# MSS_TOPRCM register map
Vendor: Texas Instruments
Registers are 32-bit, read-write, no defined reset value unless marked. A register's access mark holds for its fields unless they carry their own. Offsets are as the file gives them; [hi:lo] are bit positions; {n}, {i} and the like mark numbered series; <NAME> marks a mode.

## MSS_TOPRCM (part 2 of 2)
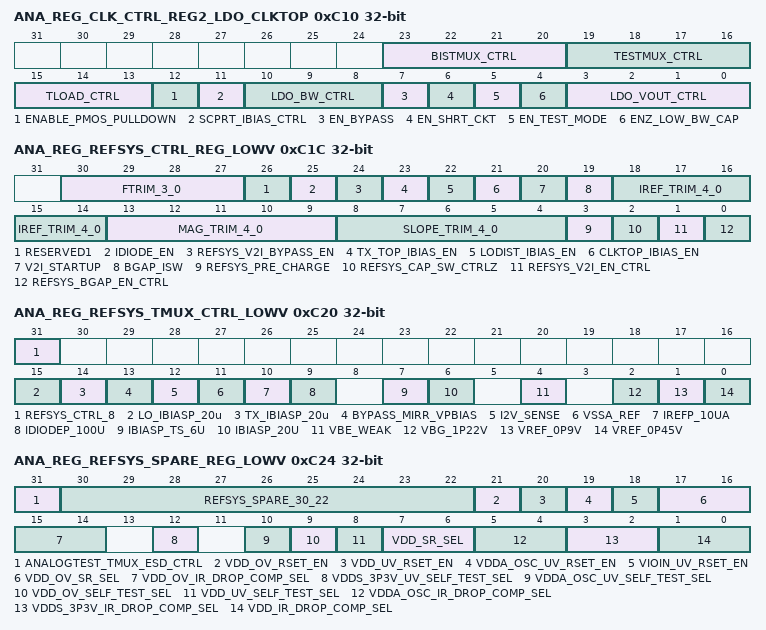
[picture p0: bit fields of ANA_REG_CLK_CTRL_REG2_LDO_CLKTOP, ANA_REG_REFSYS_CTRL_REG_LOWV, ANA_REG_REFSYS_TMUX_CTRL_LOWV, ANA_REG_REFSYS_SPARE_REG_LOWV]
0xC10 ANA_REG_CLK_CTRL_REG2_LDO_CLKTOP
  [23:20] BISTMUX_CTRL — SLICER LDO BIST MUX CONTROL (ONE HOT) Analog MUX enables to BIST output port 0000 = HI-Z Output 0001 = VBG_0P9*10/9 =1.0 V 0010 = VDD18*0.5 = 0.9V 0100 = VLDO Output * 0.6 1000 = Floating WARNING: Enabling more than one bit may damage the device 0x4 = Functional Reset
  [19:16] TESTMUX_CTRL — SLICER LDO TEST MUX CONTROL (ONE HOT) Analog MUX enables to test output port 0000 = HI-Z Output 0001 = 0.6 * VLDO_OUT 0010 = VDD18*0.5 = 0.9V 0100 = VSSA 1000 = LDO Test Current (12.5uA) WARNING: Enabling more than one bit may damage the device 0x0 = Functional Reset
  [15:13] TLOAD_CTRL — SLICER LDO TLOAD CONTROL updated description needed 0x0 = Functional Reset
  [12] ENABLE_PMOS_PULLDOWN — SLICER LDO PMOS PULL DOWN ENABLE 0 = Slicer LDO PMOS Pull Down disabled 1 = Slicer LDO PMOS Pull Down enabled 0x0 = Functional Reset
  [11] SCPRT_IBIAS_CTRL — SLICER LDO SHORT CKT PROTECTION IBIAS CONTROL 0 = Nominal short circuit bias with nominal short circuit current limit 1 = 2X Nominal short circuit bias with higher short circuit current limit 0x0 = Functional Reset
  [10:8] LDO_BW_CTRL — SLICER LDO BANDWIDTH CONTROL need updated description 0x7 = Functional Reset
  [7] EN_BYPASS — SLICER LDO BYPASS ENABLE 0 = Slicer LDO in normal mode 1 = Slicer LDO Bypassed with external voltage 0x0 = Functional Reset
  [6] EN_SHRT_CKT — SLICER LDO SHORT CKT PROTECTION ENABLE 0 = Slicer LDO Short Ckt Protection Disabled 1 = Slicer LDO Short Ckt Protection Enabled 0x0= Functional Reset
  [5] EN_TEST_MODE — SLICER LDO TEST MODE ENABLE 0 = Slicer LDO TEST MODE Disabled 1 = Slicer LDO TEST MODE Enabled 0x0 = Functional Reset
  [4] ENZ_LOW_BW_CAP — SLICER LDO LOW BW MODE DISABLE 1 = Slicer LDO Low BW mode Enabled 0 = Slicer LDO Low BW mode Disabled 0x1 = Functional Reset
  [3:0] LDO_VOUT_CTRL — SLICER LDO VOUT TRIM NEEDS updated description 0x0 = Functional Reset
0xC18 ANA_REG_CLK_STATUS_REG ro
  [0] SLICER_LDO_SC_OUT — SLICER LDO SHORT CIRCUIT INDICATOR 0 = Normal operation 1 = LDO Output Short Circuit Detected
0xC1C ANA_REG_REFSYS_CTRL_REG_LOWV
  [30:27] FTRIM_3_0 — Filter TRIM Control 0x0 = Functional Reset
  [26] RESERVED1 — <7> Unused 0x0 = Functional Reset
  [25] IDIODE_EN — <6> Idiode Active Low Control --> Unused in TPR, Reserved for AWR <0> - Enable <1> - Disable 0x0= Functional Reset
  [24] REFSYS_V2I_BYPASS_EN — <5> REFSYS V2I By-Pass Enable 0x0 = Functional Reset
  [23] TX_TOP_IBIAS_EN — <4> TX TOP IBIAS EN--> Unused in TPR, Reserved for AWR 0x1 = Functional Reset
  [22] LODIST_IBIAS_EN — <3> LO DIST BIAS EN --> Unused in TPR, Reserved for AWR 0x1 = Functional Reset
  [21] CLKTOP_IBIAS_EN — <2> CLK TOP IBIAS EN 0x1 = Functional Reset
  [20] V2I_STARTUP — <1> V2I Startup 0x0 = Functional Reset
  [19] BGAP_ISW — <0> BGAP ISW STARTUP 0x0 = Functional Reset
  [18:14] IREF_TRIM_4_0 — Default Resistor Trim for NOM LOT 0x02 = Functional Reset
  [13:9] MAG_TRIM_4_0 — Default Magnitude Trim for NOM LOT 0x00 = Functional Reset
  [8:4] SLOPE_TRIM_4_0 — Default Slope Trim for NOM LOT 0x0D = Functional Reset
  [3] REFSYS_PRE_CHARGE — REFSYS Pre Charge Control 0 = Disable Pre Charge Block 1 = Enable Pre Charge Block 0x0 = Functional Reset
  [2] REFSYS_CAP_SW_CTRLZ — REFSYS Cap Switch Control 0 = Switch External Cap to reference output 1 = Disconnect External Cap to Reference output 0x0 = Functional Reset
  [1] REFSYS_V2I_EN_CTRL — REFSYS Enable Control 0 = Disable V2I REFSYS 1 = Enable V2I REFSYS 0x1 = Functional Reset
  [0] REFSYS_BGAP_EN_CTRL — REFSYS Enable Control 0 = Disable REFSYS 1 = Enable REFSYS 0x1 = Functional Reset
0xC20 ANA_REG_REFSYS_TMUX_CTRL_LOWV
  [31] REFSYS_CTRL_8 — REFSYS Test Mux Enable. Other bits in Bus are One-hot. This control enabled in sync with other one hot control bits in Reg 0 = TMUX Disabled 1 = TMUX Enabled 0x0 = Functional Reset
  [15] LO_IBIASP_20u — <15> LO IBG BIASP 20uA (TMUX One-Hot) 0x0 = Functional Reset
  [14] TX_IBIASP_20u — <14> TX IBG BIASP 20uA (TMUX One-Hot) 0x0 = Functional Reset
  [13] BYPASS_MIRR_VPBIAS — VPBIAS Control for IREF Gen Test Mode V2I By-Pass Feature 0x0 = Functional Reset
  [12] I2V_SENSE — Sense Voltage from the BIST I2V cinversion of 20u and 6u bias current paths Sense voltage of 1V for BIST select<6> Sense voltage of 0.3V for BIST select<7> 0x0 = Functional Reset
  [11] VSSA_REF — <11> VSSA REF (TMUX One-Hot) 0x0 = Functional Reset
  [10] IREFP_10UA — <10> IREFP 10uA (TMUX One-Hot) 0x0 = Functional Reset
  [9] IDIODEP_100U — <9> Idiode BIASP 100uA (TMUX One-Hot) 0x0 = Functional Reset
  [7] IBIASP_TS_6U — <7> IBG BIASP TS 6uA (TMUX One-Hot) 0x0 = Functional Reset
  [6] IBIASP_20U — <6> CLK IBG BIASP 20uA (TMUX One-Hot) 0x0 = Functional Reset
  [4] VBE_WEAK — <4> - VBE Weak (TMUX One-Hot) 0x0 = Functional Reset
  [2] VBG_1P22V — <2> - VBG 1.22V (TMUX One-Hot) 0x0 = Functional Reset
  [1] VREF_0P9V — <1> - VREF 0P9V (Cap Node) (TMUX One-Hot) 0x0 = Functional Reset
  [0] VREF_0P45V — <0> - VREF 0P45 (TMUX One-Hot) 0x0 = Functional Reset
0xC24 ANA_REG_REFSYS_SPARE_REG_LOWV
  [31] ANALOGTEST_TMUX_ESD_CTRL — ANALOGTEST TMUX ESD CTRL in Pad-Frame (formerly RX_REFSYS_TMUX_SPARE_CTRL_LOWV<31> in AWR/IWR devices, but RX does not exist in TPR) 0x0 = Functional Reset
  [30:22] REFSYS_SPARE_30_22 — Reserved Reads return 0x0 and writes have no effect. 0x000 = Functional Reset
  [21] VDD_OV_RSET_EN — If asserted, VDD_OV will automatically reset the device through hardware control. Otherwise, UV flag will propagate to the digital where the CPU will need to take action. 0x0 = Functional Reset
  [20] VDD_UV_RSET_EN — If asserted, VDD_UV will automatically reset the device through hardware control. Otherwise, UV flag will propagate to the digital where the CPU will need to take action. 0x0 = Functional Reset
  [19] VDDA_OSC_UV_RSET_EN — If asserted, VDDA_OSC_UV will automatically reset the device through hardware control. Otherwise, UV flag will propagate to the digital where the CPU will need to take action. 0x0 = Functional Reset
  [18] VIOIN_UV_RSET_EN — If asserted, VIOIN_UV will automatically reset the device through hardware control. Otherwise, UV flag will propagate to the digital where the CPU will need to take action. 0x0 = Functional Reset
  [17:16] VDD_OV_SR_SEL — Final level of VDD 1.2V VMON OV Reference Selection See definition in REFSYS_SPARE_REG<15:14> 0x0 = Functional Reset
  [15:14] VDD_OV_IR_DROP_COMP_SEL — VDD 1.2V VMON OV Reference Selection Reference selection is dependent on REFSYS_SPARE_REG<17:16> programming If REFSYS_SPARE_REG<17:16> = 0x0 0x0 = 0.68V 0x1 = 0.67V 0x2 = 0.66V 0x3 = 0.65V If REFSYS_SPARE_REG<17:16> = 0x1 0x0 = 0.65V 0x1 = 0.64V 0x2 = 0.63V 0x3 = 0.62V If REFSYS_SPARE_REG<17:16> = 0x2 0x0 = 0.62V 0x1 = 0.61V 0x2 = 0.6V 0x3 = 0.59V If REFSYS_SPARE_REG<17:16> = 0x3 0x0 = 0.59V 0x1 = 0.58V 0x2 = 0.57V 0x3 = 0.56V 0x0 = Functional Reset
  [12] VDDS_3P3V_UV_SELF_TEST_SEL — Enable VIOIN Strict UV VMON Self Test If Self-test mode is enabled, VIOIN UV VMON reference is programmed as follows for REFSYS_SPARE_REG<3:2>: 0x0 = 0.66V 0x1 = 0.64V 0x2 = 0.62V 0x3 = 0.6V 0x0 = Functional Reset
  [10] VDDA_OSC_UV_SELF_TEST_SEL — Enable VDDA_OSC Strict UV VMON Self Test If Self-test mode is enabled, VDDA_OSC UV VMON reference is programmed as follows for REFSYS_SPARE_REG<5:4>: 0x0 = 0.66V 0x1 = 0.64V 0x2 = 0.62V 0x3 = 0.6V 0x0 = Functional Reset
  [9] VDD_OV_SELF_TEST_SEL — Enable 1.2V VDD Strict OV VMON Self Test If Self-test mode is enabled, VDD 1.2V VMON OV reference is programmed based on REFSYS_SPARE_REG<1:0> as follows: If REFSYS_SPARE_REG<7:6> = 0x0, REFSYS_SPARE_REG<1:0>: 0x0 = 0.58V 0x1 = 0.57V 0x2 = 0.56V 0x3 = 0.55V If REFSYS_SPARE_REG<7:6> = 0x1, REFSYS_SPARE_REG<1:0>: 0x0 = 0.55V 0x1 = 0.54V 0x2 = 0.53V 0x3 = 0.52V If REFSYS_SPARE_REG<7:6> = 0x2, REFSYS_SPARE_REG<1:0>: 0x0 = 0.53V 0x1 = 0.52V 0x2 = 0.51V 0x3 = 0.5V If REFSYS_SPARE_REG<7:6> = 0x3, REFSYS_SPARE_REG<1:0>: 0x0 = 0.51V 0x1 = 0.5V 0x2 = 0.49V 0x3 = 0.48V 0x0 = Functional Reset
  [8] VDD_UV_SELF_TEST_SEL — Enable 1.2V VDD Strict UV VMON Self Test If Self-test mode is enabled, VDD 1.2V VMON UV reference is programmed based on REFSYS_SPARE_REG<15:14> as follows: If REFSYS_SPARE_REG<17:16> = 0x0, REFSYS_SPARE_REG<15:14>: 0x0 = 0.68V 0x1 = 0.67V 0x2 = 0.66V 0x3 = 0.65V If REFSYS_SPARE_REG<17:16> = 0x1, REFSYS_SPARE_REG<15:14>: 0x0 = 0.65V 0x1 = 0.64V 0x2 = 0.63V 0x3 = 0.62V If REFSYS_SPARE_REG<17:16> = 0x2, REFSYS_SPARE_REG<15:14>: 0x0 = 0.62V 0x1 = 0.61V 0x2 = 0.6V 0x3 = 0.59V If REFSYS_SPARE_REG<17:16> = 0x3, REFSYS_SPARE_REG<15:14>: 0x0 = 0.59V 0x1 = 0.58V 0x2 = 0.57V 0x3 = 0.56V 0x0 = Functional Reset
  [7:6] VDD_SR_SEL — Final level of VDD 1.2V VMON UV Reference Selection See definition in REFSYS_SPARE_REG<1:0> 0x0 = Functional Reset
  [5:4] VDDA_OSC_IR_DROP_COMP_SEL — VDDA_OSC UV VMON Reference Selection 0x0 = 0.56V 0x1 = 0.54V 0x2 = 0.52V 0x3 = 0.5V 0x0 = Functional Reset
  [3:2] VDDS_3P3V_IR_DROP_COMP_SEL — VIOIN VMON UV Reference Selection 0x0 = 0.56V 0x1 = 0.54V 0x2 = 0.52V 0x3 = 0.5V 0x0 = Functional Reset
  [1:0] VDD_IR_DROP_COMP_SEL — VDD 1.2V VMON UV Reference Selection Reference selection is dependent on REFSYS_SPARE_REG<7:6> programming If REFSYS_SPARE_REG<7:6> = 0x0 0x0 = 0.58V 0x1 = 0.57V 0x2 = 0.56V 0x3 = 0.55V If REFSYS_SPARE_REG<7:6> = 0x1 0x0 = 0.55V 0x1 = 0.54V 0x2 = 0.53V 0x3 = 0.52V If REFSYS_SPARE_REG<7:6> = 0x2 0x0 = 0.53V 0x1 = 0.52V 0x2 = 0.51V 0x3 = 0.5V If REFSYS_SPARE_REG<7:6> = 0x3 0x0 = 0.51V 0x1 = 0.5V 0x2 = 0.49V 0x3 = 0.48V 0x0 = Functional Reset
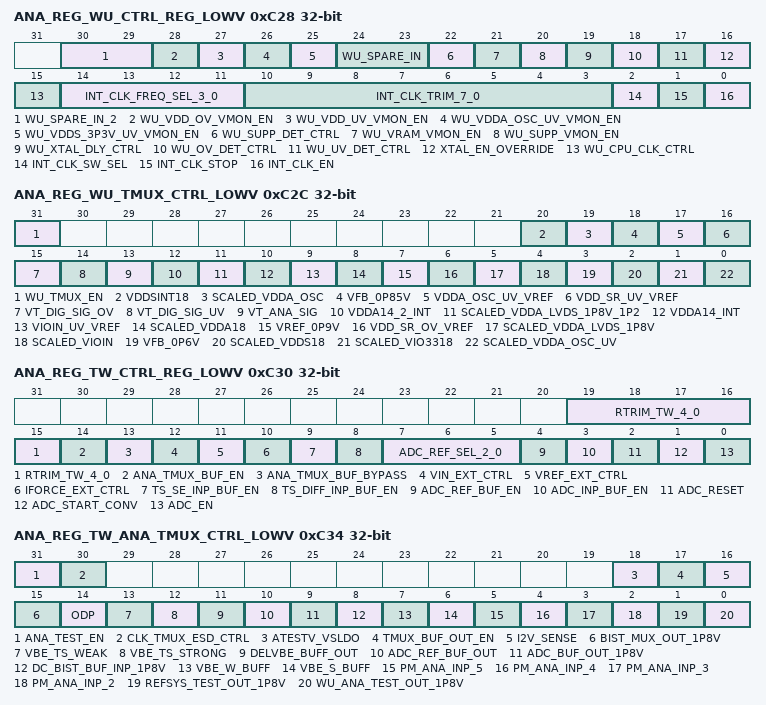
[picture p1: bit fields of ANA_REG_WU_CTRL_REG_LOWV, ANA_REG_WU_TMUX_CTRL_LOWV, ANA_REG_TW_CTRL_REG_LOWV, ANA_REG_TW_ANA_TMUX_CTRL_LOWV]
0xC28 ANA_REG_WU_CTRL_REG_LOWV
  [30:29] WU_SPARE_IN_2 — WU Spare Control 0x3 = Functional Reset
  [28] WU_VDD_OV_VMON_EN — WU VDD OV VMON Enable Control 0 = VDD OV Detect Disabled 1 = VDD OV Detect Enabled 0x0 = Functional Reset
  [27] WU_VDD_UV_VMON_EN — WU VDD UV VMON Enable Control 0 = VDD UV Detect Disabled 1 = VDD UV Detect Enabled 0x0 = Functional Reset
  [26] WU_VDDA_OSC_UV_VMON_EN — WU VDDA OSC UV VMON Enable Control 0 = VDDA OSC UV Detect Disabled 1 = VDDA OSC UV Detect Enabled 0x0 = Functional Reset
  [25] WU_VDDS_3P3V_UV_VMON_EN — WU VDDS 3.3V UV VMON Enable Control 0 = VDDS 3.3V UV Detect Disabled 1 = VDDS 3.3V UV Detect Enabled 0x0 = Functional Reset
  [24:23] WU_SPARE_IN — WU Spare Control Change for 1642 ES2P0 Change Name : Newly added OR gates to provide options to bypass crude VDD DET (also refer to <11>) Bit <0> of this field when HIGH over rides the crude VDD_DET, this control is using firmware Bit<0> of this field is WU_CTRL_REG<23> Change for 2243 ES1P0 Using Bit<1>, is WU_CTRL_REG<24> This bit is used to make the reset fix SW controllable. Manshul's email notes-- Since the default value of WU_SPARE_IN<1> is ‘0’, we will have the fix active by default. To disable it, firmware can write this bit to ‘1’ before enabling VMON. 0x0 = Functional Reset
  [22] WU_SUPP_DET_CTRL — WU VMON Detect Status Override Disable in Functional Test SOP 0 = VMON Det Status Override Disabled 1 = VMON Det Status Override Enabled 0x1 = Functional Reset
  [21] WU_VRAM_VMON_EN — WU VRAM VMON Enable Control 0 = SRAM UV Detect Disabled 1 = SRAM UV Detect Enabled 0x1 = Functional Reset
  [20] WU_SUPP_VMON_EN — WU VMON Enable Control 0 = VMON Control Disabled 1 = VMON Control Enabled 0x1 = Functional Reset
  [19] WU_XTAL_DLY_CTRL — Introduce additional delay for XTAL settling 0 = Default delay as per WU-SEQ 1 = Introduce additional delay as per WU-SEQ 0x0 = Functional Reset
  [18] WU_OV_DET_CTRL — WU Over Voltage Detect Control Changed for 1243 ES3P0 (Metal only change from 1642 ES2P0) Change Name : FW control of VDD OV DET EN 1 = OV Detect is disabled 0 = OV Detect is Enabled 0x1 = Functional Reset
  [17] WU_UV_DET_CTRL — WU Under Voltage Detect Control 0 = UV Detect is disabled 1 = UV Detect is Enabled 0x1 = Functional Reset
  [16] XTAL_EN_OVERRIDE — XTAL EN Override (WU-SEQ) Control 0 = XTAL Enable is driven by WU-SEQ detection 1 = Override XTAL Enable if disabled by default 0x0 = Functional Reset
  [15] WU_CPU_CLK_CTRL — WU CLK Control 0 = CLK Monitor Function in Dig Sequencer is disabled 1 = REF CLK Monitor Function is Enabled 0x1 = Functional Reset
  [14:11] INT_CLK_FREQ_SEL_3_0 — WU Internal Clock (RCOSC) Frequency Select Bit<3> is used as override for VMON on Untrimmed devices. Bit <3> is '1' if device REFSYS_TOP is trimmed. Changed on 1642 ES2P0 Change Name : Newly added mux for CLK MON EN options When Bit<2> = 0, MASK_CPU_CLK_OUT_CTRL_LOWV == WU_CTRL_REG<12>, essentially Bit<1> of this field When Bit<2> = 1, MASK_CPU_CLK_OUT_CTRL_LOWV == (original function) INTER_MASK_CPU_CLK_OUT_CTRL_LOWV Change Name : Newly added OR gates to provide options to bypass crude VDD DET (also refer to <23>) Bit <0> of this field when HIGH over rides the crude VDD_DET 0x0 = Functional Reset
  [10:3] INT_CLK_TRIM_7_0 — WU lnternal Clock (RCOSC) Trim 0x4B = Functional Reset (If not trimmed)
  [2] INT_CLK_SW_SEL — WU Internal Clock (RCOSC) SW_SEL 0 = TBD 1 = TBD 0x1 = Functional Reset
  [1] INT_CLK_STOP — WU Internal Clock (RCOSC) STOP 0 = Internal CLK can be enabled 1 = Internal CLK is OFF 0x0 = Functional Reset
  [0] INT_CLK_EN — WU Internal Clock (RCOSC) ENABLE 0 = Internal CLK Disabled 1 = Internal CLK Enabled 0x1 = Functional Reset
0xC2C ANA_REG_WU_TMUX_CTRL_LOWV
  [31] WU_TMUX_EN — WU TMUX Enable 0 = TMUX Disabled 1 = TMUX Enabled 0x0 = Functional Reset
  [20] VDDSINT18 — VIOIN scaled supply for VIOIN Detect Scaling Factor: VIOIN*(52/90) 0x0 = Functional Reset
  [19] SCALED_VDDA_OSC — Scaled VDDA_OSC supply for crude supply detect Scaling Factor: VDDA_OSC*(22/39) 0x0 = Functional Reset
  [18] VFB_0P85V — Scaled VDD 1.2V used as reference for VDDA_OSC crude supply detect 0x0 = Functional Reset
  [17] VDDA_OSC_UV_VREF — Test Mux Control. One Hot Control VDDA_OSC UV VMON reference 0x0 = Functional Reset
  [16] VDD_SR_UV_VREF — Test Mux Control. One Hot Control VDD UV VMON reference 0x0 = Functional Reset
  [15] VT_DIG_SIG_OV — Test Mux Control. One Hot Control Connected to Crude Vt-based VDD OV VMON reference 0x0 = Functional Reset
  [14] VT_DIG_SIG_UV — Test Mux Control. One Hot Control Connected to Crude Vt-based VDD UV VMON reference 0x0 = Functional Reset
  [13] VT_ANA_SIG — Test Mux Control. One Hot Control VT Detect Signal Level on VDDA18_PM in TPR VT Detect Signal Level on VDDA_LVDS_1P8V 0x0 = Functional Reset
  [12] VDDA14_2_INT — Test Mux Control. One Hot Control Tied LO in TPR VIN_13RF2 0x0 = Functional Reset
  [11] SCALED_VDDA_LVDS_1P8V_1P2 — Test Mux Control. One Hot Control Change in TPR VDDS_3P3V IO DET reference (1.8V mode) Scaling Factor: 0.67 * VDDA_LVDS_1P8V 0x0 = Functional Reset
  [10] VDDA14_INT — Test Mux Control. One Hot Control Tied LO in TPR VIN_13RF1 0x0 = Functional Reset
  [9] VIOIN_UV_VREF — Test Mux Control. One Hot Control Reference voltage for VIOIN_UV VMON 0x0 = Functional Reset
  [8] SCALED_VDDA18 — Test Mux Control. One Hot Control Tied LO in TPR Scaling Factor: 0.55 * VIN_18BB 0x0 = Functional Reset
  [7] VREF_0P9V — Test Mux Control. One Hot Control VREF_0P9V 0x0 = Functional Reset
  [6] VDD_SR_OV_VREF — Test Mux Control. One Hot Control VDD OV VMON reference 0x0 = Functional Reset
  [5] SCALED_VDDA_LVDS_1P8V — Test Mux Control. One Hot Control Change in TPR VDDS_3P3V IO DET reference (3.3V mode) Scaling Factor: 0.4 * VDDA_LVDS_1P8V 0x0 = Functional Reset
  [4] SCALED_VIOIN — Test Mux Control. One Hot Control Change for 1642 ES2P0 Change Name : VIOIN & VIN_SRAM connection to GPADC Scaling Factor: 0.289 * VIOIN 0x0 = Functional Reset
  [3] VFB_0P6V — Test Mux Control. One Hot Control Scaling Factor: 0.5 * VDD 0x0 = Functional Reset
  [2] SCALED_VDDS18 — Test Mux Control. One Hot Control Tied LO in TPR Scaling Factor: 0.55 * VDDS18 0x0 = Functional Reset
  [1] SCALED_VIO3318 — Test Mux Control. One Hot Control Scaling Factor: VIOIN/5.5 (3.3V mode), VIOIN/3 (1.8V mode) 0x0 = Functional Reset
  [0] SCALED_VDDA_OSC_UV — Test Mux Control. One Hot Control Scaling Factor: VDDA_OSC/3 0x0 = Functional Reset
0xC30 ANA_REG_TW_CTRL_REG_LOWV
  [19:15] RTRIM_TW_4_0 — RTRIM value to TW routed to BIST MUX IN REFSYS for I2V 0x02 = Functional Reset
  [14] ANA_TMUX_BUF_EN — TW ANA TMUX Buffer Enabled 0 = ANA TMUX Buffer Disabled 1 = ANA TMUX Buffer Enabled 0x0 = Functional Reset
  [13] ANA_TMUX_BUF_BYPASS — TW ANA TMUX Buffer Bypass 0 = ANA TMUX Buffer By-pass Disabled 1 = ANA TMUX Buffer By-pass Enabled 0x0 = Functional Reset
  [12] VIN_EXT_CTRL — TW VIN Control from External Source 0 = External VIN Control Disabled 1 = External VIN Control Enabled 0x0 = Functional Reset
  [11] VREF_EXT_CTRL — TW VREF Control from External SOurce 0 = External VREF Control Disabled 1 = External VREF Control Enabled 0x0 = Functional Reset
  [10] IFORCE_EXT_CTRL — TW Iforce Control from External Source 0 = IFORCE Control Disabled 1 = IFORCE Control Enabled 0x0 = Functional Reset
  [9] TS_SE_INP_BUF_EN — TW ADC TS SE Inp Buffer Enable 0 = Input Buffer disabled 1 = Input Buffer Enabled 0x0 = Functional Reset
  [8] TS_DIFF_INP_BUF_EN — TW ADC TS DIFF Inp Buffer Enable 0 = Input Buffer disabled 1 = Input Buffer Enabled 0x1 = Functional Reset
  [7:5] ADC_REF_SEL_2_0 — TW ADC Reference Select 0b001 = Reference from Top Refsys 0b010 = Reference from RX Refsys 0b100 = Reference from External Test Pin (CZ/ Trim) 0x001 = Functional Reset
  [4] ADC_REF_BUF_EN — TW ADC Reference Buffer Enable 0 = Input Buffer disabled 1 = Input Buffer Enabled (Default) 0x1 = Functional Reset
  [3] ADC_INP_BUF_EN — TW ADC Input Buffer Enable 0 = Input Buffer disabled 1 = Input Buffer Enabled (Default) 0x1 = Functional Reset
  [2] ADC_RESET — TW ADC Reset (Active High) 0 = ADC Out of Reset 1 = ADC In Reset 0x1 = Functional Reset
  [1] ADC_START_CONV — TW ADC Start Conversion 0x0 = Functional Reset
  [0] ADC_EN — TW ADC Control 0 = ADC Disable 1 = ADC Enable 0x0 = Functional Reset
0xC34 ANA_REG_TW_ANA_TMUX_CTRL_LOWV
  [31] ANA_TEST_EN — TW ANA Test MUX Enabled 0 = ANA TMUX Control Disabled 1 = ANA TMUX Control Enabled 0x0 = Functional Reset
  [30] CLK_TMUX_ESD_CTRL — CLK TMUX ESD CTRL in Pad-Frame 0x0 = Functional Reset
  [18] ATESTV_VSLDO — Enable Output of ATESTV of VSLDO 0x0 = Functional Reset
  [17] TMUX_BUF_OUT_EN — Enable Output of TMUX buffer 0x0 = Functional Reset
  [16] I2V_SENSE — I2V Sense Voltage of External IREF Forced. IREF is forced thru' ANAMUX Pin and enabling TW_CTRL_REG<10> 0x0 = Functional Reset
  [15] BIST_MUX_OUT_1P8V — BIST Mux output pre ADC input Buffer 0x0 = Functional Reset
  [14] ODP — Ibias current from Top Refsys for measurement on Test Pin 0x0 = Functional Reset
  [13] VBE_TS_WEAK — Single PNP Sense voltage for TSENSE selected 0x0 = Functional Reset
  [12] VBE_TS_STRONG — Multi PNP Sense voltage for TSENSE selected 0x0 = Functional Reset
  [11] DELVBE_BUFF_OUT — Difference TSENSE signal delVbe scaled and buffered for chosen TSENSE element 0x0 = Functional Reset
  [10] ADC_REF_BUF_OUT — ADC reference buffer out to Test Pin 0x0 = Functional Reset
  [9] ADC_BUF_OUT_1P8V — Buffered output of ADC inputs to GPADC 0x0 = Functional Reset
  [8] DC_BIST_BUF_INP_1P8V — DC BIST Buffered output of RX, TX, CLK, LO (shorted on to this net). DC BIST one hot control and DC BIST control has to be used to bring relevant signal here 0x0 = Functional Reset
  [7] VBE_W_BUFF — Buffered value of Weak PNP 0x0 = Functional Reset
  [6] VBE_S_BUFF — Buffered value of Strong PNP 0x0 = Functional Reset
  [5] PM_ANA_INP_5 — CLK ANA Test Pin Mapped 0x0 = Functional Reset
  [4] PM_ANA_INP_4 — RX ANA Test Mux Control 0x0 = Functional Reset
  [3] PM_ANA_INP_3 — LODIST ANA Test Mux Control 0x0 = Functional Reset
  [2] PM_ANA_INP_2 — TX PM ANA Test Mux Control 0x0 = Functional Reset
  [1] REFSYS_TEST_OUT_1P8V — Mux Output of Refsys Test Mux. Refsys Test Mux has to be enabled and controlled to bring the internal signal of Refsys Analog - PMTOP 0x0 = Functional Reset
  [0] WU_ANA_TEST_OUT_1P8V — Mux Output of WU Test Mux. WU Test Mux has to be enabled and controlled to bring the internal signal of WU Analog 0x0 = Functional Reset
0xC38 ANA_REG_TW_SPARE_LOWV
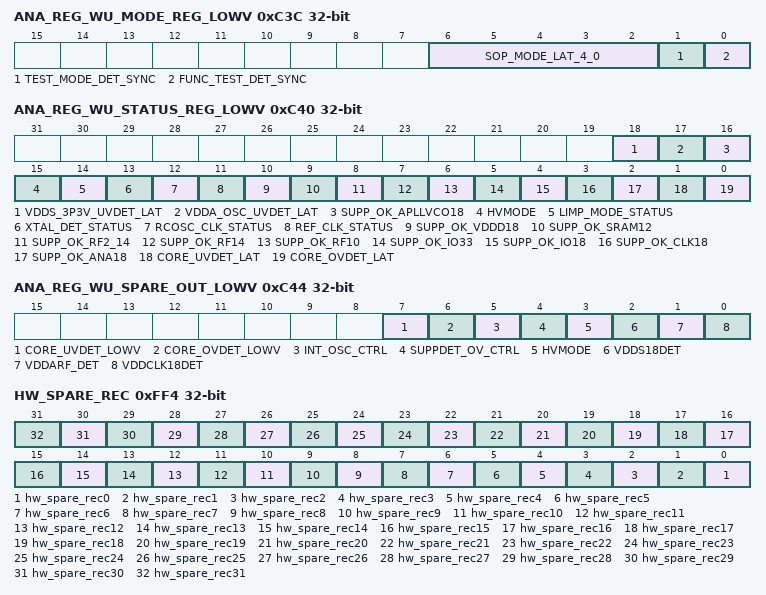
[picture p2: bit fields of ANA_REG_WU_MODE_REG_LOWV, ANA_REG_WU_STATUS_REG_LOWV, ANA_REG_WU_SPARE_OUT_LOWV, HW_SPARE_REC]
0xC3C ANA_REG_WU_MODE_REG_LOWV ro
  [6:2] SOP_MODE_LAT_4_0 — SOP Mode Latched Output
  [1] TEST_MODE_DET_SYNC — Latched Output of Test Mode Detect SOP
  [0] FUNC_TEST_DET_SYNC — Latched Output of Functional Test Mode SOP
0xC40 ANA_REG_WU_STATUS_REG_LOWV ro
  [18] VDDS_3P3V_UVDET_LAT — New in TPR: Latched Value of 3.3V IO UV Detect 0 = UV Detect Not Triggered 1 = UV Detect has Triggered
  [17] VDDA_OSC_UVDET_LAT — Latched value of UV detect of LOMULT 1.8V supply (AWR devices) For TPR, Latched Value of UV Detect of VDDA_OSC 0 = UV Detect Not Triggered 1 = UV Detect has Triggered
  [16] SUPP_OK_APLLVCO18 — Supp Detect output of APLL VCO 1.8V 0 = Supply Not detected 1 = Supply Detected Tied LO in TPR (Unused VMON)
  [15] HVMODE — HVMODE Status from VMON 1 = 3.3V VIO 0 = 1.8V VIO
  [14] LIMP_MODE_STATUS — Ref CLK status at Wake-up 0 = REF CLK is present 1 = REF CLK is absent and CPU CLK Switched to RCOSC
  [13] XTAL_DET_STATUS — XTAL Detect status at Wake-up 0 = XTAL absent 1 = XTAL Present
  [12] RCOSC_CLK_STATUS — RCOSC status at Wake-up 0 = RCOSC CLK absent 1 = RCOSC CLK Present
  [11] REF_CLK_STATUS — Ref CLK status at Wake-up 0 = REF CLK absent 1 = REF CLK Present
  [10] SUPP_OK_VDDD18 — Supp Detect output of LVDS 1.8V 0 = Supply Not detected 1 = Supply Detected Tied LO in TPR (Unused VMON)
  [9] SUPP_OK_SRAM12 — UV Detect Status of SRAM 0 = UV Not Detected 1 = UV Detected Tied LO in TPR (Unused VMON)
  [8] SUPP_OK_RF2_14 — Supp Detect output of RF2 1.4V Pin 0 = Supply Not detected 1 = Supply Detected Tied LO in TPR (Unused VMON)
  [7] SUPP_OK_RF14 — Updated for 1642 ES2P0 Change name : Mux for VIN_13 OK in LDO bypass mode This output bit is always tied low Tied LO in TPR and AWR/IWR devices
  [6] SUPP_OK_RF10 — Updated for 1642 ES2P0 Change name : Mux for VIN_13 OK in LDO bypass mode When RF_LDO_BYPASS_EN = 1, this bit will be high when the supply is > 0.75 When RF_LDO_BYPASS_EN = 0, this bit will be high when the supply is > 1.05 Tied LO in TPR (Unused VMON)
  [5] SUPP_OK_IO33 — Supp Detect output of IO 3.3V 0 = Supply Not detected 1 = Supply Detected
  [4] SUPP_OK_IO18 — Supp Detect output of IO 1.8V 0 = Supply Not detected 1 = Supply Detected
  [3] SUPP_OK_CLK18 — Supp Detect output of CLK 1.8V 0 = Supply Not detected 1 = Supply Detected For TPR, Crude detection of VDDA_OSC
  [2] SUPP_OK_ANA18 — Supp Detect output of Ana 1.8V Tied LO in TPR (unused VMON) 0 = Supply Not detected 1 = Supply Detected
  [1] CORE_UVDET_LAT — Latched Value of UV Detect 0 = UV Detect Not Triggered 1 = UV Detect has Triggered
  [0] CORE_OVDET_LAT — Latched Value of OV Detect 0 = OV Detect Not Triggered 1 = OV Detect has Triggered
0xC44 ANA_REG_WU_SPARE_OUT_LOWV ro
  [7] CORE_UVDET_LOWV — UV Detect of Core Supply-Unlatched
  [6] CORE_OVDET_LOWV — OV Detect of Core Supply-Unlatched
  [5] INT_OSC_CTRL — Internal Oscillator Control
  [4] SUPPDET_OV_CTRL — Supply Detect Override Bit
  [3] HVMODE — Status of VIO supply. 3.3V or 1.8V
  [2] VDDS18DET — Status of 1.8V IO Bias Supply
  [1] VDDARF_DET — Status of 1.3V RF Supply
  [0] VDDCLK18DET — Status of 1.8V CLK Supply
{0xFD0+4i} HW_SPARE_RW{i} (i=0..3)
  [31:0] hw_spare_rw{i} — Reserved for HW R&D
{0xFE0+4i} HW_SPARE_RO{i} ro (i=0..3)
  [31:0] hw_spare_ro{i} — Reserved for HW R&D
0xFF0 HW_SPARE_WPH
  [31:0] hw_spare_wph — Reserved for HW R&D
0xFF4 HW_SPARE_REC
  [n] hw_spare_rec{n} (n=0..31) — Reserved for HW R&D
0x1008 LOCK0_KICK0 — - KICK0 component
  [31:0] ?
0x100C LOCK0_KICK1 — - KICK1 component
  [31:0] ?
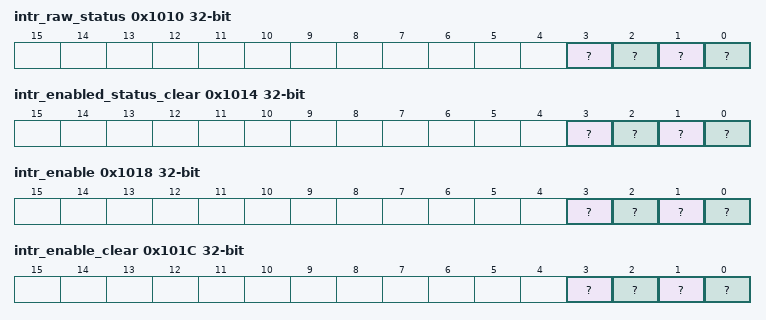
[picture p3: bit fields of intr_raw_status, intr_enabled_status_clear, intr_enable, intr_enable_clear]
0x1010 intr_raw_status — Interrupt Raw Status/Set Register
  [3] ? — Proxy0 access violation error. Raw status is read. Write a 1 to set the status. Writing a 0 has no effect.
  [2] ? — Kick access violation error. Raw status is read. Write a 1 to set the status. Writing a 0 has no effect.
  [1] ? — Addressing violation error. Raw status is read. Write a 1 to set the status. Writing a 0 has no effect.
  [0] ? — Protection violation error. Raw status is read. Write a 1 to set the status. Writing a 0 has no effect.
0x1014 intr_enabled_status_clear — Interrupt Enabled Status/Clear register
  [3] ? — Proxy0 access violation error. Enabled status is read. Write a 1 to clear the status. Writing a 0 has no effect.
  [2] ? — Kick access violation error. Enabled status is read. Write a 1 to clear the status. Writing a 0 has no effect.
  [1] ? — Addressing violation error. Enabled status is read. Write a 1 to clear the status. Writing a 0 has no effect.
  [0] ? — Protection violation error. Enabled status is read. Write a 1 to clear the status. Writing a 0 has no effect.
0x1018 intr_enable — Interrupt Enable register
  [3] ? — Proxy0 access violation error enable. Write a 1 to set the enable. Writing a 0 has no effect.
  [2] ? — Kick access violation error enable. Write a 1 to set the enable. Writing a 0 has no effect.
  [1] ? — Addressing violation error enable. Write a 1 to set the enable. Writing a 0 has no effect.
  [0] ? — Protection violation error enable. Write a 1 to set the enable. Writing a 0 has no effect.
0x101C intr_enable_clear — Interrupt Enable Clear register
  [3] ? — Proxy0 access violation error enable clear. Write a 1 to clear the enable. Writing a 0 has no effect.
  [2] ? — Kick access violation error enable clear. Write a 1 to clear the enable. Writing a 0 has no effect.
  [1] ? — Addressing violation error enable clear. Write a 1 to clear the enable. Writing a 0 has no effect.
  [0] ? — Protection violation error enable clear. Write a 1 to clear the enable. Writing a 0 has no effect.
0x1020 eoi
  [7:0] ? — EOI vector value. Write this with interrupt distribution value in the chip.
0x1024 fault_address ro
  [31:0] ? — Fault Address.
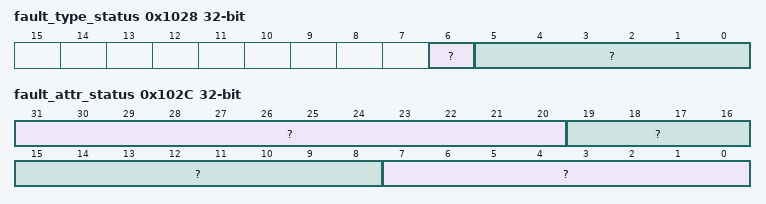
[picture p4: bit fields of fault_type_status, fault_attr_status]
0x1028 fault_type_status ro
  [6] ? — Non-secure access.
  [5:0] ? — Fault Type 10_0000 = Supervisor read fault - priv = 1 dir = 1 dtype != 1 01_0000 = Supervisor write fault - priv = 1 dir = 0 00_1000 = Supervisor execute fault - priv = 1 dir = 1 dtype = 1 00_0100 = User read fault - priv = 0 dir = 1 dtype = 1 00_0010 = User write fault - priv = 0 dir = 0 00_0001 = User execute fault - priv = 0 dir = 1 dtype = 1 00_0000 = No fault
0x102C fault_attr_status ro — Fault Attribute Status register
  [31:20] ? — XID.
  [19:8] ? — Route ID.
  [7:0] ? — Privilege ID.
0x1030 fault_clear wo
  [0] ? — Fault clear. Writing a 1 clears the current fault. Writing a 0 has no effect.
